AUTOSAR XML (schema 4-0-3)
standard types defined: UInt32, UInt8
package /AUTOSAR_Platform/DataConstrs
  range DC_UInt8: raw 0..255
package /PATAC/MSM/ComponentTypes
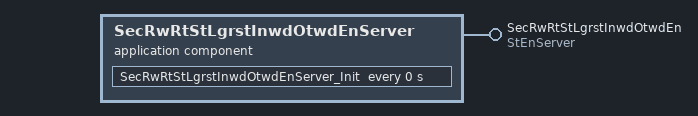
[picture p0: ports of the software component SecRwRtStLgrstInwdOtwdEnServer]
  application sw component type SecRwRtStLgrstInwdOtwdEnServer
    provide port SecRwRtStLgrstInwdOtwdEn: provided-com-specs=[{operation=Clear, queue-length=1}, {operation=Get, queue-length=1}, {operation=Set, queue-length=1}], provided-interface=StEnServer
    behavior SecRwRtStLgrstInwdOtwdEnServer_InternalBehavior
      operation invoked event OIT_SecRwRtStLgrstInwdOtwdEn_Clear_SecRwRtStLgrstInwdOtwdEn_Clear: start-on-event=SecRwRtStLgrstInwdOtwdEn_Clear, operation=SecRwRtStLgrstInwdOtwdEn.Clear
      operation invoked event OIT_SecRwRtStLgrstInwdOtwdEn_Get_SecRwRtStLgrstInwdOtwdEn_Get: start-on-event=SecRwRtStLgrstInwdOtwdEn_Get, operation=SecRwRtStLgrstInwdOtwdEn.Get
      operation invoked event OIT_SecRwRtStLgrstInwdOtwdEn_Set_SecRwRtStLgrstInwdOtwdEn_Set: start-on-event=SecRwRtStLgrstInwdOtwdEn_Set, operation=SecRwRtStLgrstInwdOtwdEn.Set
      timing event SecRwRtStLgrstInwdOtwdEnServer_InitEvent: start-on-event=SecRwRtStLgrstInwdOtwdEnServer_Init, period=0
      4 x runnable:
        SecRwRtStLgrstInwdOtwdEn_Clear
        SecRwRtStLgrstInwdOtwdEn_Get
        SecRwRtStLgrstInwdOtwdEn_Set
        SecRwRtStLgrstInwdOtwdEnServer_Init
  swc implementation SecRwRtStLgrstInwdOtwdEnServer_Implementation: behavior=SecRwRtStLgrstInwdOtwdEnServer_InternalBehavior
    code-descriptors:
      code Default: artifact-descriptors=autosar-engineering-object={short-label=Default, category=SWSRC}
package /PATAC/MSM/ModeAdjust/PortInterface
  client server interface StEnServer
    operation Clear
      arg data: type=UInt8, direction=IN, server-argument-impl-policy=USE-ARGUMENT-TYPE
    operation Get
      arg data: type=UInt32, direction=OUT, server-argument-impl-policy=USE-ARGUMENT-TYPE
    operation Set
      arg data: type=UInt8, direction=IN, server-argument-impl-policy=USE-ARGUMENT-TYPE
